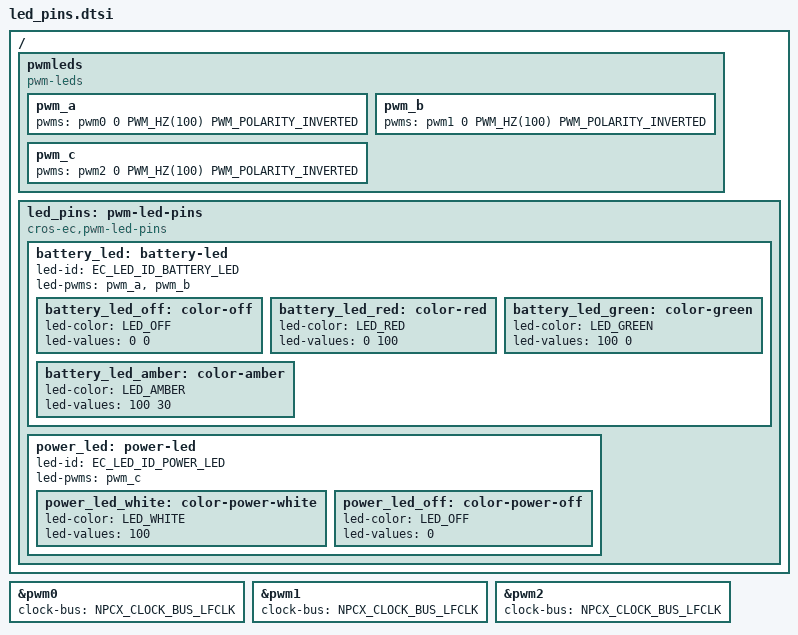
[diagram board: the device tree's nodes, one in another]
/* Copyright 2026 The ChromiumOS Authors
 * Use of this source code is governed by a BSD-style license that can be
 * found in the LICENSE file.
 */

/ {
	pwmleds {
		compatible = "pwm-leds";
		pwm_a: pwm_a {
			pwms = <&pwm0 0 PWM_HZ(100) PWM_POLARITY_INVERTED>;
		};
		pwm_b: pwm_b {
			pwms = <&pwm1 0 PWM_HZ(100) PWM_POLARITY_INVERTED>;
		};
		pwm_c: pwm_c {
			pwms = <&pwm2 0 PWM_HZ(100) PWM_POLARITY_INVERTED>;
		};

	};

	led_pins: pwm-led-pins {
		compatible = "cros-ec,pwm-led-pins";

		battery_led: battery-led {
			led-id = "EC_LED_ID_BATTERY_LED";
			led-pwms = <&pwm_a &pwm_b>;

			battery_led_off: color-off {
				led-color = "LED_OFF";
				led-values = <0 0>;
			};

			battery_led_red: color-red {
				led-color = "LED_RED";
				led-values = <0 100>;
			};

			battery_led_green: color-green {
				led-color = "LED_GREEN";
				led-values = <100 0>;
			};

			battery_led_amber: color-amber {
				led-color = "LED_AMBER";
				led-values = <100 30>;
			};
		};

		power_led: power-led {
			led-id = "EC_LED_ID_POWER_LED";
			led-pwms = <&pwm_c>;

			power_led_white: color-power-white {
				led-color = "LED_WHITE";
				led-values = <100>;
			};

			power_led_off: color-power-off {
				led-color = "LED_OFF";
				led-values = <0>;
			};
		};

	};
};

/* EC_LED1_ODL */
&pwm0 {
	clock-bus = "NPCX_CLOCK_BUS_LFCLK";
};

/* EC_LED2_ODL */
&pwm1 {
	clock-bus = "NPCX_CLOCK_BUS_LFCLK";
};

/* EC_PWRBTN_LED_CTRL */
&pwm2 {
	clock-bus = "NPCX_CLOCK_BUS_LFCLK";
};
